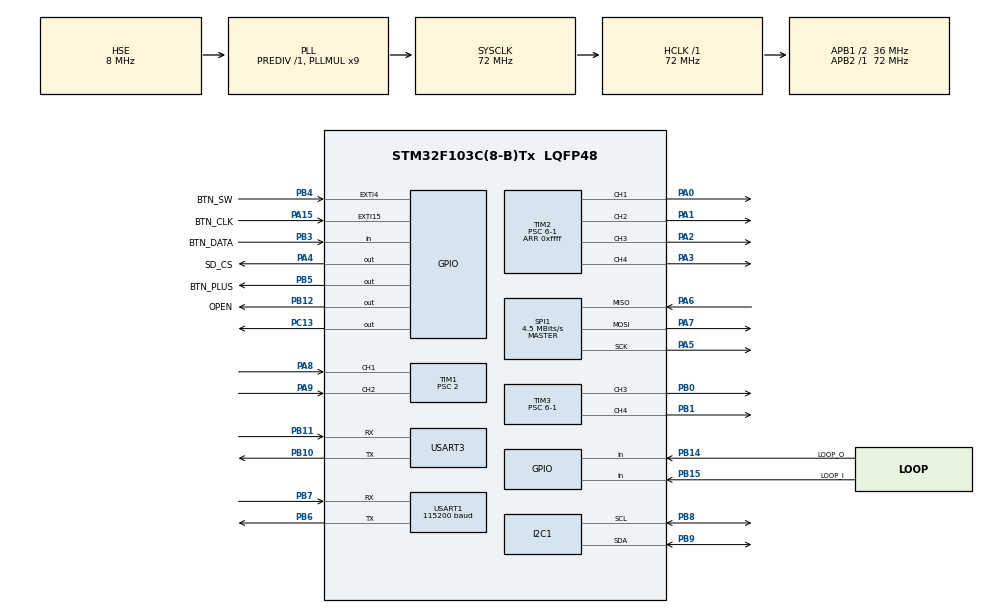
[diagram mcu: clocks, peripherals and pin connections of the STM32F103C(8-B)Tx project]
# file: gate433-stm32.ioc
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FATFS._FS_MINIMIZE=0
FATFS._FS_NORTC=1
FATFS._FS_TINY=0
FATFS._USE_MKFS=0
FATFS._USE_STRFUNC=0
Mcu.Family=STM32F1
Mcu.Name=STM32F103C(8-B)Tx
Mcu.Package=LQFP48
NVIC.EXTI15_10_IRQn=true\:1\:0\:true\:false\:true\:true
NVIC.EXTI4_IRQn=true\:1\:0\:true\:false\:true\:true
NVIC.I2C1_ER_IRQn=true\:0\:0\:true\:false\:true\:true
NVIC.I2C1_EV_IRQn=true\:0\:0\:true\:false\:true\:true
NVIC.PriorityGroup=NVIC_PRIORITYGROUP_4
NVIC.TIM1_CC_IRQn=true\:0\:0\:false\:false\:true\:true
NVIC.TIM1_UP_IRQn=true\:1\:0\:true\:false\:true\:true
NVIC.USART1_IRQn=true\:1\:0\:true\:false\:true\:true
NVIC.USART3_IRQn=true\:1\:0\:true\:false\:true\:true
PA0-WKUP.GPIO_ModeDefaultPP=GPIO_MODE_AF_OD
PA0-WKUP.GPIO_Speed=GPIO_SPEED_FREQ_LOW
PA0-WKUP.Signal=S_TIM2_CH1_ETR
PA1.GPIO_ModeDefaultPP=GPIO_MODE_AF_OD
PA1.GPIO_Speed=GPIO_SPEED_FREQ_LOW
PA1.Signal=S_TIM2_CH2
PA13.Mode=Serial_Wire
PA13.Signal=SYS_JTMS-SWDIO
PA14.Mode=Serial_Wire
PA14.Signal=SYS_JTCK-SWCLK
PA15.GPIO_Label=BTN_CLK
PA15.GPIO_ModeDefaultEXTI=GPIO_MODE_IT_RISING_FALLING
PA15.GPIO_PuPd=GPIO_PULLUP
PA15.Signal=GPXTI15
PA2.GPIO_ModeDefaultPP=GPIO_MODE_AF_OD
PA2.GPIO_Speed=GPIO_SPEED_FREQ_LOW
PA2.Signal=S_TIM2_CH3
PA3.GPIO_ModeDefaultPP=GPIO_MODE_AF_OD
PA3.GPIO_Speed=GPIO_SPEED_FREQ_LOW
PA3.Signal=S_TIM2_CH4
PA4.GPIO_Label=SD_CS
PA4.GPIO_Speed=GPIO_SPEED_FREQ_MEDIUM
PA4.PinState=GPIO_PIN_SET
PA4.Signal=GPIO_Output
PA5.Mode=Full_Duplex_Master
PA5.Signal=SPI1_SCK
PA6.Mode=Full_Duplex_Master
PA6.Signal=SPI1_MISO
PA7.Mode=Full_Duplex_Master
PA7.Signal=SPI1_MOSI
PA8.Signal=S_TIM1_CH1
PA9.Signal=S_TIM1_CH2
PB0.GPIO_ModeDefaultPP=GPIO_MODE_AF_OD
PB0.GPIO_Speed=GPIO_SPEED_FREQ_LOW
PB0.Signal=S_TIM3_CH3
PB1.GPIO_ModeDefaultPP=GPIO_MODE_AF_OD
PB1.GPIO_Speed=GPIO_SPEED_FREQ_LOW
PB1.Signal=S_TIM3_CH4
PB10.Mode=Asynchronous
PB10.Signal=USART3_TX
PB11.Mode=Asynchronous
PB11.Signal=USART3_RX
PB12.GPIO_Label=OPEN
PB12.GPIO_ModeDefaultOutputPP=GPIO_MODE_OUTPUT_OD
PB12.PinState=GPIO_PIN_SET
PB12.Signal=GPIO_Output
PB14.GPIO_Label=LOOP_O
PB14.GPIO_PuPd=GPIO_PULLDOWN
PB14.Signal=GPIO_Input
PB15.GPIO_Label=LOOP_I
PB15.GPIO_PuPd=GPIO_PULLDOWN
PB15.Signal=GPIO_Input
PB3.GPIO_Label=BTN_DATA
PB3.GPIO_PuPd=GPIO_PULLUP
PB3.Signal=GPIO_Input
PB4.GPIO_Label=BTN_SW
PB4.GPIO_ModeDefaultEXTI=GPIO_MODE_IT_RISING_FALLING
PB4.GPIO_PuPd=GPIO_PULLUP
PB4.Signal=GPXTI4
PB5.GPIO_Label=BTN_PLUS
PB5.PinState=GPIO_PIN_SET
PB5.Signal=GPIO_Output
PB6.Mode=Asynchronous
PB6.Signal=USART1_TX
PB7.Mode=Asynchronous
PB7.Signal=USART1_RX
PB8.Mode=I2C
PB8.Signal=I2C1_SCL
PB9.Mode=I2C
PB9.Signal=I2C1_SDA
PC13-TAMPER-RTC.PinState=GPIO_PIN_SET
PC13-TAMPER-RTC.Signal=GPIO_Output
PC14-OSC32_IN.Mode=LSE-External-Oscillator
PC14-OSC32_IN.Signal=RCC_OSC32_IN
PC15-OSC32_OUT.Mode=LSE-External-Oscillator
PC15-OSC32_OUT.Signal=RCC_OSC32_OUT
PD0-OSC_IN.Mode=HSE-External-Oscillator
PD0-OSC_IN.Signal=RCC_OSC_IN
PD1-OSC_OUT.Mode=HSE-External-Oscillator
PD1-OSC_OUT.Signal=RCC_OSC_OUT
ProjectManager.HeapSize=0x200
ProjectManager.StackSize=0x400
ProjectManager.TargetToolchain=SW4STM32
RCC.AHBFreq_Value=72000000
RCC.APB1CLKDivider=RCC_HCLK_DIV2
RCC.APB1Freq_Value=36000000
RCC.APB1TimFreq_Value=72000000
RCC.APB2Freq_Value=72000000
RCC.APB2TimFreq_Value=72000000
RCC.HCLKFreq_Value=72000000
RCC.PLLMUL=RCC_PLL_MUL9
RCC.PLLSourceVirtual=RCC_PLLSOURCE_HSE
RCC.SYSCLKFreq_VALUE=72000000
RCC.SYSCLKSource=RCC_SYSCLKSOURCE_PLLCLK
RCC.USBFreq_Value=48000000
RCC.USBPrescaler=RCC_USBCLKSOURCE_PLL_DIV1_5
SH.S_TIM1_CH1.0=TIM1_CH1,Input_Capture1_from_TI1
SH.S_TIM1_CH2.0=TIM1_CH2,Input_Capture2_from_TI2
SH.S_TIM2_CH1_ETR.0=TIM2_CH1,PWM Generation1 CH1
SH.S_TIM2_CH2.0=TIM2_CH2,PWM Generation2 CH2
SH.S_TIM2_CH3.0=TIM2_CH3,PWM Generation3 CH3
SH.S_TIM2_CH4.0=TIM2_CH4,PWM Generation4 CH4
SH.S_TIM3_CH3.0=TIM3_CH3,PWM Generation3 CH3
SH.S_TIM3_CH4.0=TIM3_CH4,PWM Generation4 CH4
SPI1.BaudRatePrescaler=SPI_BAUDRATEPRESCALER_16
SPI1.CalculateBaudRate=4.5 MBits/s
SPI1.Direction=SPI_DIRECTION_2LINES
SPI1.Mode=SPI_MODE_MASTER
SPI1.VirtualType=VM_MASTER
TIM1.Channel-Input_Capture1_from_TI1=TIM_CHANNEL_1
TIM1.Channel-Input_Capture2_from_TI2=TIM_CHANNEL_2
TIM1.ClockDivision=TIM_CLOCKDIVISION_DIV1
TIM1.ICPolarity_CH1=TIM_INPUTCHANNELPOLARITY_FALLING
TIM1.ICPolarity_CH2=TIM_INPUTCHANNELPOLARITY_RISING
TIM1.Period=0xffff
TIM1.Prescaler=2
TIM1.TIM_MasterSlaveMode=TIM_MASTERSLAVEMODE_DISABLE
TIM2.Channel-PWM\ Generation1\ CH1=TIM_CHANNEL_1
TIM2.Channel-PWM\ Generation2\ CH2=TIM_CHANNEL_2
TIM2.Channel-PWM\ Generation3\ CH3=TIM_CHANNEL_3
TIM2.Channel-PWM\ Generation4\ CH4=TIM_CHANNEL_4
TIM2.OCPolarity_1=TIM_OCPOLARITY_LOW
TIM2.OCPolarity_2=TIM_OCPOLARITY_LOW
TIM2.OCPolarity_3=TIM_OCPOLARITY_LOW
TIM2.OCPolarity_4=TIM_OCPOLARITY_LOW
TIM2.Period=0xffff
TIM2.Prescaler=6-1
TIM2.Pulse-PWM\ Generation1\ CH1=0
TIM2.Pulse-PWM\ Generation2\ CH2=0
TIM2.Pulse-PWM\ Generation3\ CH3=0
TIM2.Pulse-PWM\ Generation4\ CH4=0
TIM3.Channel-PWM\ Generation3\ CH3=TIM_CHANNEL_3
TIM3.Channel-PWM\ Generation4\ CH4=TIM_CHANNEL_4
TIM3.OCPolarity_3=TIM_OCPOLARITY_LOW
TIM3.OCPolarity_4=TIM_OCPOLARITY_LOW
TIM3.Period=0xffff
TIM3.Prescaler=6-1
TIM3.Pulse-PWM\ Generation3\ CH3=0
TIM3.Pulse-PWM\ Generation4\ CH4=0
USART1.BaudRate=115200
USART1.VirtualMode=VM_ASYNC
USART3.VirtualMode=VM_ASYNC
VP_FATFS_VS_Generic.Mode=User_defined
VP_RTC_No_RTC_Output.Mode=RTC_OUT_NO
VP_RTC_VS_RTC_Activate.Mode=RTC_Enabled
VP_TIM1_VS_ClockSourceINT.Mode=Internal
VP_TIM2_VS_ClockSourceINT.Mode=Internal
VP_TIM3_VS_ClockSourceINT.Mode=Internal
board=gate433-stm32

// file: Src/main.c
/**
  ******************************************************************************
  * File Name          : main.c
  * Description        : Main program body
  ******************************************************************************
  * This notice applies to any and all portions of this file
  * that are not between comment pairs USER CODE BEGIN and
  * USER CODE END. Other portions of this file, whether
  * inserted by the user or by software development tools
  * are owned by their respective copyright owners.
  *
  * Copyright (c) 2018 STMicroelectronics International N.V.
  * All rights reserved.
  *
  * Redistribution and use in source and binary forms, with or without
  * modification, are permitted, provided that the following conditions are met:
  *
  * 1. Redistribution of source code must retain the above copyright notice,
  *    this list of conditions and the following disclaimer.
  * 2. Redistributions in binary form must reproduce the above copyright notice,
  *    this list of conditions and the following disclaimer in the documentation
  *    and/or other materials provided with the distribution.
  * 3. Neither the name of STMicroelectronics nor the names of other
  *    contributors to this software may be used to endorse or promote products
  *    derived from this software without specific written permission.
  * 4. This software, including modifications and/or derivative works of this
  *    software, must execute solely and exclusively on microcontroller or
  *    microprocessor devices manufactured by or for STMicroelectronics.
  * 5. Redistribution and use of this software other than as permitted under
  *    this license is void and will automatically terminate your rights under
  *    this license.
  *
  * THIS SOFTWARE IS PROVIDED BY STMICROELECTRONICS AND CONTRIBUTORS "AS IS"
  * AND ANY EXPRESS, IMPLIED OR STATUTORY WARRANTIES, INCLUDING, BUT NOT
  * LIMITED TO, THE IMPLIED WARRANTIES OF MERCHANTABILITY, FITNESS FOR A
  * PARTICULAR PURPOSE AND NON-INFRINGEMENT OF THIRD PARTY INTELLECTUAL PROPERTY
  * RIGHTS ARE DISCLAIMED TO THE FULLEST EXTENT PERMITTED BY LAW. IN NO EVENT
  * SHALL STMICROELECTRONICS OR CONTRIBUTORS BE LIABLE FOR ANY DIRECT, INDIRECT,
  * INCIDENTAL, SPECIAL, EXEMPLARY, OR CONSEQUENTIAL DAMAGES (INCLUDING, BUT NOT
  * LIMITED TO, PROCUREMENT OF SUBSTITUTE GOODS OR SERVICES; LOSS OF USE, DATA,
  * OR PROFITS; OR BUSINESS INTERRUPTION) HOWEVER CAUSED AND ON ANY THEORY OF
  * LIABILITY, WHETHER IN CONTRACT, STRICT LIABILITY, OR TORT (INCLUDING
  * NEGLIGENCE OR OTHERWISE) ARISING IN ANY WAY OUT OF THE USE OF THIS SOFTWARE,
  * EVEN IF ADVISED OF THE POSSIBILITY OF SUCH DAMAGE.
  *
  ******************************************************************************
  */

#include "main.h"
#include "stm32f1xx_hal.h"
#include "fatfs.h"
#include "i2c.h"
#include "rtc.h"
#include "spi.h"
#include "tim.h"
#include "usart.h"
#include "gpio.h"

/* USER CODE BEGIN PV */
/* Private variables ---------------------------------------------------------*/

/* USER CODE END PV */

void SystemClock_Config(void);

/* USER CODE BEGIN PFP */
/* Private function prototypes -----------------------------------------------*/
void _MainLoop();

/* USER CODE END PFP */

int main(void)
{

  /* MCU Configuration----------------------------------------------------------*/

  /* Reset of all peripherals, Initializes the Flash interface and the Systick. */
  HAL_Init();

  /* Configure the system clock */
  SystemClock_Config();

  /* Initialize all configured peripherals */
  MX_GPIO_Init();
  MX_SPI1_Init();
  MX_USART1_UART_Init();
  MX_I2C1_Init();
  MX_TIM1_Init();
  MX_USART3_UART_Init();
  MX_RTC_Init();
  MX_TIM2_Init();
  MX_TIM3_Init();

  /* USER CODE BEGIN 2 */
  HAL_TIM_Base_Start(&htim2);
  HAL_TIM_Base_Start(&htim3);
  HAL_TIM_PWM_Start(&htim2, TIM_CHANNEL_1);
  HAL_TIM_PWM_Start(&htim2, TIM_CHANNEL_2);
  HAL_TIM_PWM_Start(&htim2, TIM_CHANNEL_3);
  HAL_TIM_PWM_Start(&htim2, TIM_CHANNEL_4);
  HAL_TIM_PWM_Start(&htim3, TIM_CHANNEL_3);
  HAL_TIM_PWM_Start(&htim3, TIM_CHANNEL_4);
  /* USER CODE END 2 */

  /* Infinite loop */
  /* USER CODE BEGIN WHILE */
	_MainLoop();

  /* USER CODE END WHILE */

}

/** System Clock Configuration
*/
void SystemClock_Config(void)
{

  RCC_OscInitTypeDef RCC_OscInitStruct;
  RCC_ClkInitTypeDef RCC_ClkInitStruct;
  RCC_PeriphCLKInitTypeDef PeriphClkInit;

    /**Initializes the CPU, AHB and APB busses clocks
    */
  RCC_OscInitStruct.OscillatorType = RCC_OSCILLATORTYPE_LSI|RCC_OSCILLATORTYPE_HSE;
  RCC_OscInitStruct.HSEState = RCC_HSE_ON;
  RCC_OscInitStruct.HSEPredivValue = RCC_HSE_PREDIV_DIV1;
  RCC_OscInitStruct.HSIState = RCC_HSI_ON;
  RCC_OscInitStruct.LSIState = RCC_LSI_ON;
  RCC_OscInitStruct.PLL.PLLState = RCC_PLL_ON;
  RCC_OscInitStruct.PLL.PLLSource = RCC_PLLSOURCE_HSE;
  RCC_OscInitStruct.PLL.PLLMUL = RCC_PLL_MUL9;
  if (HAL_RCC_OscConfig(&RCC_OscInitStruct) != HAL_OK)
  {
    _Error_Handler(__FILE__, __LINE__);
  }

    /**Initializes the CPU, AHB and APB busses clocks
    */
  RCC_ClkInitStruct.ClockType = RCC_CLOCKTYPE_HCLK|RCC_CLOCKTYPE_SYSCLK
                              |RCC_CLOCKTYPE_PCLK1|RCC_CLOCKTYPE_PCLK2;
  RCC_ClkInitStruct.SYSCLKSource = RCC_SYSCLKSOURCE_PLLCLK;
  RCC_ClkInitStruct.AHBCLKDivider = RCC_SYSCLK_DIV1;
  RCC_ClkInitStruct.APB1CLKDivider = RCC_HCLK_DIV2;
  RCC_ClkInitStruct.APB2CLKDivider = RCC_HCLK_DIV1;

  if (HAL_RCC_ClockConfig(&RCC_ClkInitStruct, FLASH_LATENCY_2) != HAL_OK)
  {
    _Error_Handler(__FILE__, __LINE__);
  }

  PeriphClkInit.PeriphClockSelection = RCC_PERIPHCLK_RTC;
  PeriphClkInit.RTCClockSelection = RCC_RTCCLKSOURCE_LSI;
  if (HAL_RCCEx_PeriphCLKConfig(&PeriphClkInit) != HAL_OK)
  {
    _Error_Handler(__FILE__, __LINE__);
  }

    /**Configure the Systick interrupt time
    */
  HAL_SYSTICK_Config(HAL_RCC_GetHCLKFreq()/1000);

    /**Configure the Systick
    */
  HAL_SYSTICK_CLKSourceConfig(SYSTICK_CLKSOURCE_HCLK);

  /* SysTick_IRQn interrupt configuration */
  HAL_NVIC_SetPriority(SysTick_IRQn, 1, 0);
}

void _Error_Handler(char * file, int line)
{
  /* USER CODE BEGIN Error_Handler_Debug */
  /* User can add his own implementation to report the HAL error return state */
  while(1)
  {
	  HAL_GPIO_TogglePin(GPIOC, GPIO_PIN_13);
	  HAL_Delay(100);
  }
  /* USER CODE END Error_Handler_Debug */
}

/************************ (C) COPYRIGHT STMicroelectronics *****END OF FILE****/
